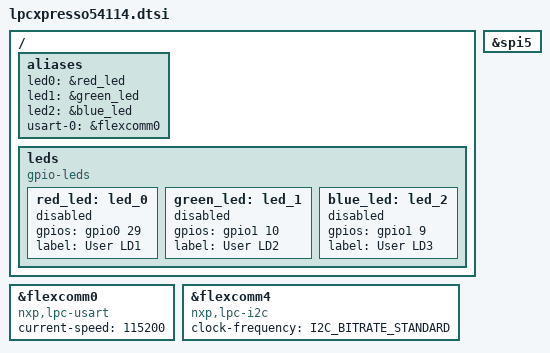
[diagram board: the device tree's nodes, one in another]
/*
 * Copyright (c) 2017, NXP
 *
 * SPDX-License-Identifier: Apache-2.0
 */

/ {
	aliases{
		led0 = &red_led;
		led1 = &green_led;
		led2 = &blue_led;
		usart-0 = &flexcomm0;
	};

	leds {
		compatible = "gpio-leds";
		red_led: led_0 {
			gpios = <&gpio0 29 0>;
			label = "User LD1";
			status = "disabled";
		};
		green_led: led_1 {
			gpios = <&gpio1 10 0>;
			label = "User LD2";
			status = "disabled";
		};
		blue_led: led_2 {
			gpios = <&gpio1 9 0>;
			label = "User LD3";
			status = "disabled";
		};
	};
};

&flexcomm0 {
	compatible = "nxp,lpc-usart";
	current-speed = <115200>;
};

arduino_i2c: &flexcomm4 {
	compatible = "nxp,lpc-i2c";
	clock-frequency = <I2C_BITRATE_STANDARD>;
	#address-cells = <1>;
	#size-cells = <0>;
};

arduino_spi: &spi5 {};
